# haltium_sysctrl register map
Vendor: Nordic Semiconductor; Series: nRFHaltium; File version: 1
Registers are 32-bit, read-write, reset 0x0 unless marked. A register's access mark holds for its fields unless they carry their own. Offsets are from the block's base; [hi:lo] are bit positions; lines under a group give offsets from that group; 'fields as' and 'values as' point back to an identical list.

## VREGVS0V8_S — VREGVS0V8
Base 0x5F965000
0x400 STATUS ro — Voltage regulator status
  [1:0] MODE — Current voltage regulator mode
    0=High power mode; 1=LowPowerRefresh (Low power mode); 2=Ultra-low power refresh mode
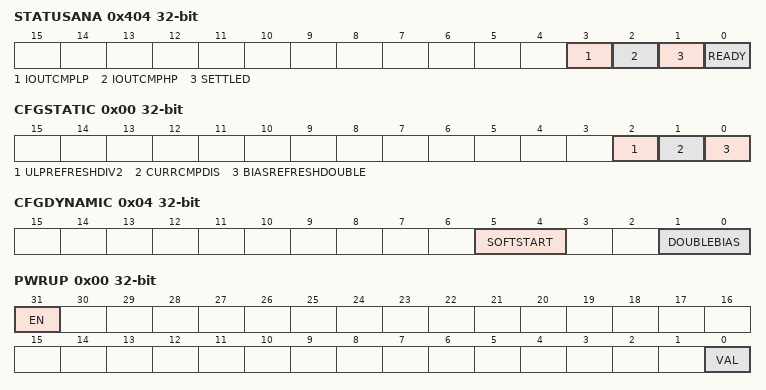
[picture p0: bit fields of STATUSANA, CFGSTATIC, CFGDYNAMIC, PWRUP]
0x404 STATUSANA ro — Status of analog module output signals
  [3] IOUTCMPLP — Current value of the IOUTCMPLP signal from the analog module
  [2] IOUTCMPHP — Current value of the IOUTCMPHP signal from the analog module
  [1] SETTLED — Current value of the SETTLED signal from the analog module
  [0] READY — Current value of the READY signal from the analog module
0x410 CONFIG group — Unspecified
  0x00 CFGSTATIC — Voltage regulator static CFG configuration
    [all] fields
      0=Disabled (Configuration disabled); 1=Enabled (Configuration enabled)
    [2] ULPREFRESHDIV2 — Divide the ULP refresh OSC by 2
    [1] CURRCMPDIS — Turn off current comparators
    [0] BIASREFRESHDOUBLE — Double the on time of the bias refresh
  0x04 CFGDYNAMIC — Voltage regulator dynamic CFG configuration
    [5:4] SOFTSTART — Current limit low configuration for the voltage regulator
      0=Automatically handled by the MMI; 1=Disabled (Current limit low disabled); 2=Enabled (Current limit low enabled)
    [1:0] DOUBLEBIAS — Double bias current configuration control
      0=Automatically handled by the MMI; 1=Disabled (Double bias current disabled); 2=Enabled (Double bias current enabled)
0x440 TRIM group — Unspecified
  0x00 VREF — Internal voltage reference trimming
    [6:0] VAL — Voltage reference trimming value
  0x04 HIGHPOWER — High power mode output voltage offset trimming
    [3:0] VAL — Voltage offset trimming value
  0x08 LOWPOWER — Low power mode output voltage offset trimming
    [3:0] VAL — Voltage offset trimming value.
0x480 MIRROR reset 0x1 — Enable LOCK for mirrored registers
  [0] LOCK — Lock for mirrored registers
    0=Disabled (Lock disabled); 1=Enabled (Lock enabled)
0x484 VOUTHP reset 0x2F — High power mode Output voltage programming
  [5:0] VAL — Output voltage value
0x488 VOUTLP reset 0x2F — Low power mode Output voltage programming
  [5:0] VAL — Output voltage value
0x48C PWRUPCTRL — Power up control
  [1:0] CTRL
    0=Automatically handled by the MMI; 1=PowerUp; 2=PowerDown
0x490 MODE — Voltage regulator mode
  [1:0] MODE
    0=Automatically handled by the MMI; 1=High power mode; 2=LowPowerRefresh (Low power mode); 3=Ultra-low power refresh mode
0x500 OVERRIDE group — Unspecified
  0x00 PWRUP — Override the PWRUP signal to the analog module
    [31] EN — Enable the override
      0=Disabled (Override is disabled); 1=Enabled (Override is enabled)
    [0] VAL — Override value for the signal
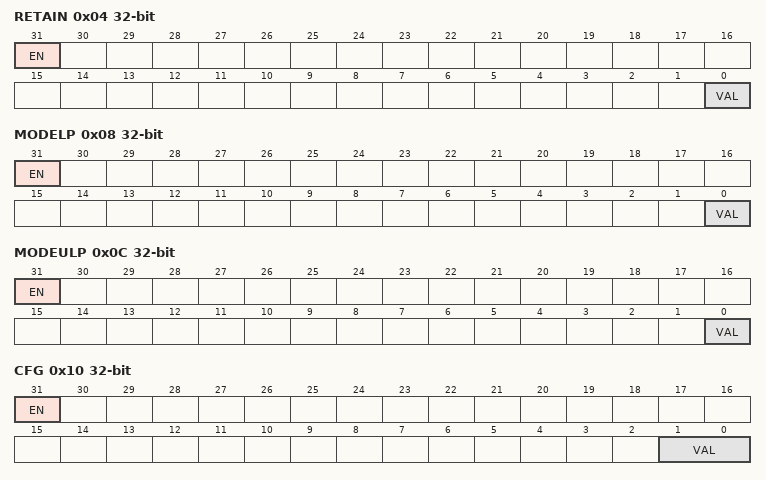
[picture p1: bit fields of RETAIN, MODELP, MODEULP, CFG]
  0x04 RETAIN — Override the RETAIN signal to the analog module
    fields as OVERRIDE.PWRUP
  0x08 MODELP — Override the MODE LP signal to the analog module
    fields as OVERRIDE.PWRUP
  0x0C MODEULP — Override the MODE ULP signal to the analog module
    fields as OVERRIDE.PWRUP
  0x10 CFG — Override the dynamic CFG[1:0] signals to the analog module
    [31] EN — Enable the override
      values as OVERRIDE.PWRUP.EN
    [1:0] VAL — Override value for the signal
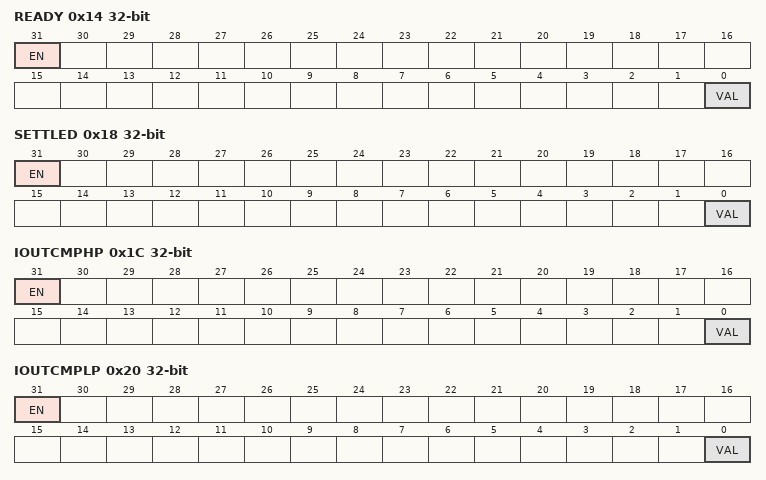
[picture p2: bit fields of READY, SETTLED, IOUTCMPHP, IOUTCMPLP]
  0x14 READY — Override the READY signal from the analog module
    [31] EN — Enable the override
      values as OVERRIDE.PWRUP.EN
    [0] VAL — Current value of the signal
  0x18 SETTLED — Override the SETTLED signal from the analog module
    fields as OVERRIDE.READY
  0x1C IOUTCMPHP — Override the IOUTCMP_HP signal from the analog module
    fields as OVERRIDE.READY
  0x20 IOUTCMPLP — Override the IOUTCMP_LP signal from the analog module
    fields as OVERRIDE.READY
0x600 DFT group — Unspecified
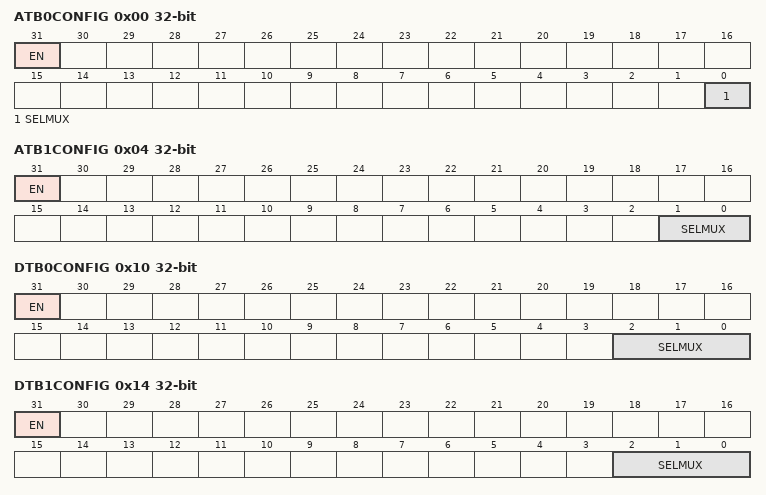
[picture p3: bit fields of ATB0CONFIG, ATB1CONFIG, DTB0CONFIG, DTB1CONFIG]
  0x00 ATB0CONFIG — Analog Test Bus 0 (ATB0) configuration
    [31] EN — Enable the analog test bus
      0=Disabled (Analog test bus is disabled); 1=Enabled (Analog test bus is enabled)
    [0] SELMUX — Select multiplexer for ATB0
      0=ExtVref (Calibration Vref input); 1=VSS
  0x04 ATB1CONFIG — Analog Test Bus 1 (ATB1) configuration
    [31] EN — Enable the analog test bus
      values as DFT.ATB0CONFIG.EN
    [1:0] SELMUX — Select multiplexer for ATB1
      0=UnbufferedHPvref; 1=BufferedLPvref; 2=VDDAO0V8 (VDD_VS_0V8)
  0x10 DTB0CONFIG — Digital Test Bus 0 (DTB0) configuration
    [31] EN — Enable the digital test bus
      0=Disabled (Digital test bus is disabled); 1=Enabled (Digital test bus is enabled)
    [2:0] SELMUX — Select multiplexer for DTB0
      0=None selected; 1=ReadyHP (LDO_HP_READY); 2=PwrupVrefBias (PWRUP_LDO_VREF_BIAS); 3=VrefChgDelayReq (LDO_VREF_CHG_DELAY_REQ); 4=PwrupHP (PWRUP_LDO_HP); 5=ReadyVrefBias (LDO_VREF_BIAS_READY); 6=ReadyIBPP (LDO_VREF_IBPP_READY); 7=VSS
  0x14 DTB1CONFIG — Digital Test Bus 1 (DTB1) configuration
    [31] EN — Enable the digital test bus
      values as DFT.DTB0CONFIG.EN
    [2:0] SELMUX — Select multiplexer for DTB1
      0=None selected; 1=ReadyLP (LDO_LP_READY); 2=CalEnable (CAL_EN_LDO); 3=VrefChgTimeoutBias (LDO_VREF_CHG_TIMEOUT_BIAS); 4=PwrupLP (PWRUP_LDO_LP); 5=SettledVrefBias (LDO_VREF_BIAS_SETTLED); 6=SettledIBPP (LDO_VREF_IBPP_SETTLED); 7=ModeULPRN (ULPR_MODE_N)
  0x1C DTB3CONFIG — Digital Test Bus 3 (DTB3) configuration
    [30] EN — Enable the PWRUP delay test circuit
      0=Disabled (PWRUP delay test circuit is disabled); 1=Enabled (PWRUP delay test circuit is enabled)
  0x30 TCFG — Test mode configuration
    [4:0] MODE
      0=Off; 17=PowerupHPcore; 18=ResetFSM (Reset initernal state machine); 20=PowerupLPcore; 24=PowerupBias
  0x34 CALEN — Calibration enable
    [0] CALEN
      0=ATCMPOff; 1=ATCMPOn
  0x38 CALCMP ro — Calibration compare
    [0] CALCMP
